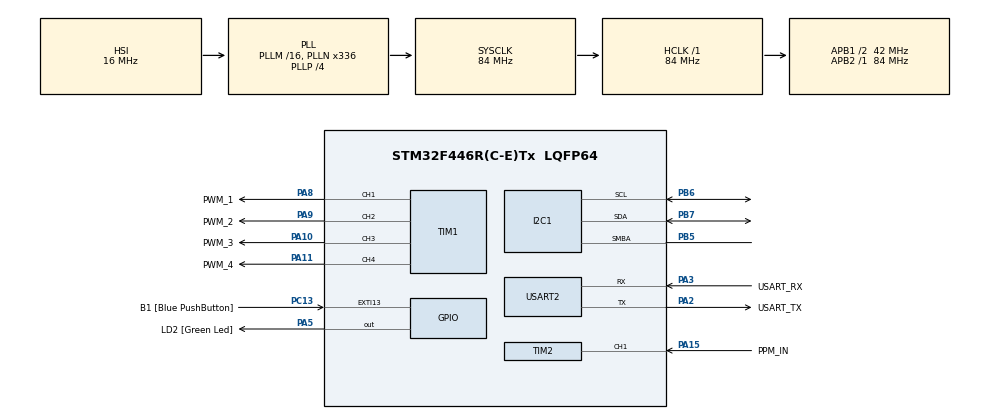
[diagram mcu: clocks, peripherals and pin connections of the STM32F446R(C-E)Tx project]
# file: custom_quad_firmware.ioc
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Mcu.Family=STM32F4
Mcu.Name=STM32F446R(C-E)Tx
Mcu.Package=LQFP64
NVIC.PriorityGroup=NVIC_PRIORITYGROUP_0
PA10.GPIO_Label=PWM_3
PA10.Signal=S_TIM1_CH3
PA11.GPIO_Label=PWM_4
PA11.Signal=S_TIM1_CH4
PA13.GPIO_Label=TMS
PA13.Mode=Serial_Wire
PA13.Signal=SYS_JTMS-SWDIO
PA14.GPIO_Label=TCK
PA14.Mode=Serial_Wire
PA14.Signal=SYS_JTCK-SWCLK
PA15.GPIO_Label=PPM_IN
PA15.Signal=S_TIM2_CH1_ETR
PA2.GPIO_Label=USART_TX
PA2.Mode=Asynchronous
PA2.Signal=USART2_TX
PA3.GPIO_Label=USART_RX
PA3.Mode=Asynchronous
PA3.Signal=USART2_RX
PA5.GPIO_Label=LD2 [Green Led]
PA5.Signal=GPIO_Output
PA8.GPIO_Label=PWM_1
PA8.Signal=S_TIM1_CH1
PA9.GPIO_Label=PWM_2
PA9.Signal=S_TIM1_CH2
PB3.GPIO_Label=SWO
PB3.Signal=SYS_JTDO-SWO
PB5.Mode=SMBus-Alert-mode
PB5.Signal=I2C1_SMBA
PB6.Mode=SMBus-Alert-mode
PB6.Signal=I2C1_SCL
PB7.Mode=SMBus-Alert-mode
PB7.Signal=I2C1_SDA
PC13.GPIO_Label=B1 [Blue PushButton]
PC13.GPIO_ModeDefaultEXTI=GPIO_MODE_IT_FALLING
PC13.Signal=GPXTI13
PC14-OSC32_IN.Mode=LSE-External-Oscillator
PC14-OSC32_IN.Signal=RCC_OSC32_IN
PC15-OSC32_OUT.Mode=LSE-External-Oscillator
PC15-OSC32_OUT.Signal=RCC_OSC32_OUT
PH0-OSC_IN.Mode=HSE-External-Oscillator
PH0-OSC_IN.Signal=RCC_OSC_IN
PH1-OSC_OUT.Mode=HSE-External-Oscillator
PH1-OSC_OUT.Signal=RCC_OSC_OUT
ProjectManager.HeapSize=0x200
ProjectManager.StackSize=0x400
ProjectManager.TargetToolchain=Makefile
RCC.48MHZClocksFreq_Value=84000000
RCC.AHBFreq_Value=84000000
RCC.APB1CLKDivider=RCC_HCLK_DIV2
RCC.APB1Freq_Value=42000000
RCC.APB1TimFreq_Value=84000000
RCC.APB2Freq_Value=84000000
RCC.APB2TimFreq_Value=84000000
RCC.CortexFreq_Value=84000000
RCC.FLatency-AdvancedSettings=FLASH_LATENCY_2
RCC.HCLKFreq_Value=84000000
RCC.HSE_VALUE=8000000
RCC.HSI_VALUE=16000000
RCC.PLLN=336
RCC.PLLP=RCC_PLLP_DIV4
RCC.SYSCLKFreq_VALUE=84000000
RCC.SYSCLKSource=RCC_SYSCLKSOURCE_PLLCLK
RCC.USBFreq_Value=168000000
RCC.VCOOutputFreq_Value=336000000
SH.S_TIM1_CH1.0=TIM1_CH1,Output Compare1 CH1
SH.S_TIM1_CH2.0=TIM1_CH2,Output Compare2 CH2
SH.S_TIM1_CH3.0=TIM1_CH3,Output Compare3 CH3
SH.S_TIM1_CH4.0=TIM1_CH4,Output Compare4 CH4
SH.S_TIM2_CH1_ETR.0=TIM2_CH1,Input_Capture1_from_TI1
TIM1.Channel-Output\ Compare1\ CH1=TIM_CHANNEL_1
TIM1.Channel-Output\ Compare2\ CH2=TIM_CHANNEL_2
TIM1.Channel-Output\ Compare3\ CH3=TIM_CHANNEL_3
TIM1.Channel-Output\ Compare4\ CH4=TIM_CHANNEL_4
TIM2.Channel-Input_Capture1_from_TI1=TIM_CHANNEL_1
USART2.VirtualMode=VM_ASYNC
VP_TIM1_VS_ClockSourceINT.Mode=Internal
VP_TIM2_VS_ClockSourceINT.Mode=Internal
board=NUCLEO-F446RE

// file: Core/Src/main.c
/* USER CODE BEGIN Header */
/**
  ******************************************************************************
  * @file           : main.c
  * @brief          : Main program body
  ******************************************************************************
  * @attention
  *
  * Copyright (c) 2021 STMicroelectronics.
  * All rights reserved.
  *
  * This software is licensed under terms that can be found in the LICENSE file
  * in the root directory of this software component.
  * If no LICENSE file comes with this software, it is provided AS-IS.
  *
  ******************************************************************************
  */
/* USER CODE END Header */
#include "main.h"
#include "pwm.h"

SMBUS_HandleTypeDef hsmbus1;

TIM_HandleTypeDef htim1;
TIM_HandleTypeDef htim2;

UART_HandleTypeDef huart2;

void SystemClock_Config(void);
static void MX_GPIO_Init(void);
static void MX_I2C1_SMBUS_Init(void);
static void MX_TIM1_Init(void);
static void MX_TIM2_Init(void);
static void MX_USART2_UART_Init(void);

int main(void)
{

  /* MCU Configuration--------------------------------------------------------*/

  /* Reset of all peripherals, Initializes the Flash interface and the Systick. */
  HAL_Init();

  /* Configure the system clock */
  SystemClock_Config();

  /* Initialize all configured peripherals */
  MX_GPIO_Init();
  MX_I2C1_SMBUS_Init();
  MX_TIM1_Init();
  MX_TIM2_Init();
  MX_USART2_UART_Init();

  /* Infinite loop */
  while (1)
  {

  }
}

void SystemClock_Config(void)
{
  RCC_OscInitTypeDef RCC_OscInitStruct = {0};
  RCC_ClkInitTypeDef RCC_ClkInitStruct = {0};

  /** Configure the main internal regulator output voltage
  */
  __HAL_RCC_PWR_CLK_ENABLE();
  __HAL_PWR_VOLTAGESCALING_CONFIG(PWR_REGULATOR_VOLTAGE_SCALE3);
  /** Initializes the RCC Oscillators according to the specified parameters
  * in the RCC_OscInitTypeDef structure.
  */
  RCC_OscInitStruct.OscillatorType = RCC_OSCILLATORTYPE_HSI;
  RCC_OscInitStruct.HSIState = RCC_HSI_ON;
  RCC_OscInitStruct.HSICalibrationValue = RCC_HSICALIBRATION_DEFAULT;
  RCC_OscInitStruct.PLL.PLLState = RCC_PLL_ON;
  RCC_OscInitStruct.PLL.PLLSource = RCC_PLLSOURCE_HSI;
  RCC_OscInitStruct.PLL.PLLM = 16;
  RCC_OscInitStruct.PLL.PLLN = 336;
  RCC_OscInitStruct.PLL.PLLP = RCC_PLLP_DIV4;
  RCC_OscInitStruct.PLL.PLLQ = 2;
  RCC_OscInitStruct.PLL.PLLR = 2;
  if (HAL_RCC_OscConfig(&RCC_OscInitStruct) != HAL_OK)
  {
    Error_Handler();
  }
  /** Initializes the CPU, AHB and APB buses clocks
  */
  RCC_ClkInitStruct.ClockType = RCC_CLOCKTYPE_HCLK|RCC_CLOCKTYPE_SYSCLK
                              |RCC_CLOCKTYPE_PCLK1|RCC_CLOCKTYPE_PCLK2;
  RCC_ClkInitStruct.SYSCLKSource = RCC_SYSCLKSOURCE_PLLCLK;
  RCC_ClkInitStruct.AHBCLKDivider = RCC_SYSCLK_DIV1;
  RCC_ClkInitStruct.APB1CLKDivider = RCC_HCLK_DIV2;
  RCC_ClkInitStruct.APB2CLKDivider = RCC_HCLK_DIV1;

  if (HAL_RCC_ClockConfig(&RCC_ClkInitStruct, FLASH_LATENCY_2) != HAL_OK)
  {
    Error_Handler();
  }
}

static void MX_I2C1_SMBUS_Init(void)
{

  hsmbus1.Instance = I2C1;
  hsmbus1.Init.ClockSpeed = 100000;
  hsmbus1.Init.OwnAddress1 = 0;
  hsmbus1.Init.AddressingMode = SMBUS_ADDRESSINGMODE_7BIT;
  hsmbus1.Init.DualAddressMode = SMBUS_DUALADDRESS_DISABLE;
  hsmbus1.Init.OwnAddress2 = 0;
  hsmbus1.Init.GeneralCallMode = SMBUS_GENERALCALL_DISABLE;
  hsmbus1.Init.NoStretchMode = SMBUS_NOSTRETCH_DISABLE;
  hsmbus1.Init.PacketErrorCheckMode = SMBUS_PEC_DISABLE;
  hsmbus1.Init.PeripheralMode = SMBUS_PERIPHERAL_MODE_SMBUS_SLAVE;
  if (HAL_SMBUS_Init(&hsmbus1) != HAL_OK)
  {
    Error_Handler();
  }
  /** configuration Alert Mode
  */
  if (HAL_SMBUS_EnableAlert_IT(&hsmbus1) != HAL_OK)
  {
    Error_Handler();
  }

}

static void MX_TIM1_Init(void)
{

  TIM_ClockConfigTypeDef sClockSourceConfig = {0};
  TIM_MasterConfigTypeDef sMasterConfig = {0};
  TIM_OC_InitTypeDef sConfigOC = {0};
  TIM_BreakDeadTimeConfigTypeDef sBreakDeadTimeConfig = {0};

  htim1.Instance = TIM1;
  htim1.Init.Prescaler = 0;
  htim1.Init.CounterMode = TIM_COUNTERMODE_UP;
  htim1.Init.Period = 65535;
  htim1.Init.ClockDivision = TIM_CLOCKDIVISION_DIV1;
  htim1.Init.RepetitionCounter = 0;
  htim1.Init.AutoReloadPreload = TIM_AUTORELOAD_PRELOAD_DISABLE;
  if (HAL_TIM_Base_Init(&htim1) != HAL_OK)
  {
    Error_Handler();
  }
  sClockSourceConfig.ClockSource = TIM_CLOCKSOURCE_INTERNAL;
  if (HAL_TIM_ConfigClockSource(&htim1, &sClockSourceConfig) != HAL_OK)
  {
    Error_Handler();
  }
  if (HAL_TIM_OC_Init(&htim1) != HAL_OK)
  {
    Error_Handler();
  }
  sMasterConfig.MasterOutputTrigger = TIM_TRGO_RESET;
  sMasterConfig.MasterSlaveMode = TIM_MASTERSLAVEMODE_DISABLE;
  if (HAL_TIMEx_MasterConfigSynchronization(&htim1, &sMasterConfig) != HAL_OK)
  {
    Error_Handler();
  }
  sConfigOC.OCMode = TIM_OCMODE_TIMING;
  sConfigOC.Pulse = 0;
  sConfigOC.OCPolarity = TIM_OCPOLARITY_HIGH;
  sConfigOC.OCNPolarity = TIM_OCNPOLARITY_HIGH;
  sConfigOC.OCFastMode = TIM_OCFAST_DISABLE;
  sConfigOC.OCIdleState = TIM_OCIDLESTATE_RESET;
  sConfigOC.OCNIdleState = TIM_OCNIDLESTATE_RESET;
  if (HAL_TIM_OC_ConfigChannel(&htim1, &sConfigOC, TIM_CHANNEL_1) != HAL_OK)
  {
    Error_Handler();
  }
  if (HAL_TIM_OC_ConfigChannel(&htim1, &sConfigOC, TIM_CHANNEL_2) != HAL_OK)
  {
    Error_Handler();
  }
  if (HAL_TIM_OC_ConfigChannel(&htim1, &sConfigOC, TIM_CHANNEL_3) != HAL_OK)
  {
    Error_Handler();
  }
  if (HAL_TIM_OC_ConfigChannel(&htim1, &sConfigOC, TIM_CHANNEL_4) != HAL_OK)
  {
    Error_Handler();
  }
  sBreakDeadTimeConfig.OffStateRunMode = TIM_OSSR_DISABLE;
  sBreakDeadTimeConfig.OffStateIDLEMode = TIM_OSSI_DISABLE;
  sBreakDeadTimeConfig.LockLevel = TIM_LOCKLEVEL_OFF;
  sBreakDeadTimeConfig.DeadTime = 0;
  sBreakDeadTimeConfig.BreakState = TIM_BREAK_DISABLE;
  sBreakDeadTimeConfig.BreakPolarity = TIM_BREAKPOLARITY_HIGH;
  sBreakDeadTimeConfig.AutomaticOutput = TIM_AUTOMATICOUTPUT_DISABLE;
  if (HAL_TIMEx_ConfigBreakDeadTime(&htim1, &sBreakDeadTimeConfig) != HAL_OK)
  {
    Error_Handler();
  }
  HAL_TIM_MspPostInit(&htim1);

}

static void MX_TIM2_Init(void)
{

  TIM_ClockConfigTypeDef sClockSourceConfig = {0};
  TIM_MasterConfigTypeDef sMasterConfig = {0};
  TIM_IC_InitTypeDef sConfigIC = {0};

  htim2.Instance = TIM2;
  htim2.Init.Prescaler = 41; // prescaler of 41 brings frequency from 84 MHz to 2 MHz
  htim2.Init.CounterMode = TIM_COUNTERMODE_UP;
  htim2.Init.Period = 40000; // with prescaler of 41, 0.02 s period (50 Hz) is established when period is 40000
  htim2.Init.ClockDivision = TIM_CLOCKDIVISION_DIV1;
  htim2.Init.AutoReloadPreload = TIM_AUTORELOAD_PRELOAD_DISABLE;
  if (HAL_TIM_Base_Init(&htim2) != HAL_OK)
  {
    Error_Handler();
  }
  sClockSourceConfig.ClockSource = TIM_CLOCKSOURCE_INTERNAL;
  if (HAL_TIM_ConfigClockSource(&htim2, &sClockSourceConfig) != HAL_OK)
  {
    Error_Handler();
  }
  if (HAL_TIM_IC_Init(&htim2) != HAL_OK)
  {
    Error_Handler();
  }
  sMasterConfig.MasterOutputTrigger = TIM_TRGO_RESET;
  sMasterConfig.MasterSlaveMode = TIM_MASTERSLAVEMODE_DISABLE;
  if (HAL_TIMEx_MasterConfigSynchronization(&htim2, &sMasterConfig) != HAL_OK)
  {
    Error_Handler();
  }
  sConfigIC.ICPolarity = TIM_INPUTCHANNELPOLARITY_RISING;
  sConfigIC.ICSelection = TIM_ICSELECTION_DIRECTTI;
  sConfigIC.ICPrescaler = TIM_ICPSC_DIV1;
  sConfigIC.ICFilter = 0;
  if (HAL_TIM_IC_ConfigChannel(&htim2, &sConfigIC, TIM_CHANNEL_1) != HAL_OK)
  {
    Error_Handler();
  }

}

static void MX_USART2_UART_Init(void)
{

  huart2.Instance = USART2;
  huart2.Init.BaudRate = 115200;
  huart2.Init.WordLength = UART_WORDLENGTH_8B;
  huart2.Init.StopBits = UART_STOPBITS_1;
  huart2.Init.Parity = UART_PARITY_NONE;
  huart2.Init.Mode = UART_MODE_TX_RX;
  huart2.Init.HwFlowCtl = UART_HWCONTROL_NONE;
  huart2.Init.OverSampling = UART_OVERSAMPLING_16;
  if (HAL_UART_Init(&huart2) != HAL_OK)
  {
    Error_Handler();
  }

}

static void MX_GPIO_Init(void)
{
  GPIO_InitTypeDef GPIO_InitStruct = {0};

  /* GPIO Ports Clock Enable */
  __HAL_RCC_GPIOC_CLK_ENABLE();
  __HAL_RCC_GPIOH_CLK_ENABLE();
  __HAL_RCC_GPIOA_CLK_ENABLE();
  __HAL_RCC_GPIOB_CLK_ENABLE();

  /*Configure GPIO pin Output Level */
  HAL_GPIO_WritePin(LD2_GPIO_Port, LD2_Pin, GPIO_PIN_RESET);

  /*Configure GPIO pin : B1_Pin */
  GPIO_InitStruct.Pin = B1_Pin;
  GPIO_InitStruct.Mode = GPIO_MODE_IT_FALLING;
  GPIO_InitStruct.Pull = GPIO_NOPULL;
  HAL_GPIO_Init(B1_GPIO_Port, &GPIO_InitStruct);

  /*Configure GPIO pin : LD2_Pin */
  GPIO_InitStruct.Pin = LD2_Pin;
  GPIO_InitStruct.Mode = GPIO_MODE_OUTPUT_PP;
  GPIO_InitStruct.Pull = GPIO_NOPULL;
  GPIO_InitStruct.Speed = GPIO_SPEED_FREQ_LOW;
  HAL_GPIO_Init(LD2_GPIO_Port, &GPIO_InitStruct);

}

void Error_Handler(void)
{
  /* USER CODE BEGIN Error_Handler_Debug */
  /* User can add his own implementation to report the HAL error return state */
  __disable_irq();
  while (1)
  {
    // setMotorPower(50, 1);
    HAL_GPIO_TogglePin(LD2_GPIO_Port, LD2_Pin);
    HAL_Delay(100);
  }
  /* USER CODE END Error_Handler_Debug */
}
